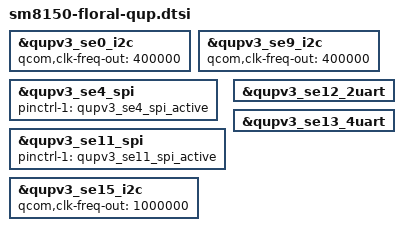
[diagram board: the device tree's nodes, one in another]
/* Copyright (c) 2018, The Linux Foundation. All rights reserved.
 *
 * This program is free software; you can redistribute it and/or modify
 * it under the terms of the GNU General Public License version 2 and
 * only version 2 as published by the Free Software Foundation.
 *
 * This program is distributed in the hope that it will be useful,
 * but WITHOUT ANY WARRANTY; without even the implied warranty of
 * MERCHANTABILITY or FITNESS FOR A PARTICULAR PURPOSE.  See the
 * GNU General Public License for more details.
 */

// flame/coral battery i2c
&qupv3_se0_i2c {
	qcom,clk-freq-out = <400000>;
};

// flame/coral pac193x i2c
&qupv3_se9_i2c {
	qcom,clk-freq-out = <400000>;
};

// Touch wants se4 pins active even in suspend.
&qupv3_se4_spi {
	pinctrl-1 = <&qupv3_se4_spi_active>;
};

// Audio wants se11 pins active even in suspend.
&qupv3_se11_spi {
	pinctrl-1 = <&qupv3_se11_spi_active>;
};

&qupv3_se12_2uart {
	status = "ok";
};

&qupv3_se13_4uart {
	status = "ok";
};

// Haptics/batt i2c
&qupv3_se15_i2c {
	qcom,clk-freq-out = <1000000>;
};

